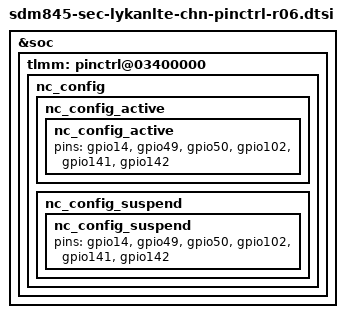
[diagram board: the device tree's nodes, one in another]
/* Copyright (c) 2016-2017, The Linux Foundation. All rights reserved.
 *
 * This program is free software; you can redistribute it and/or modify
 * it under the terms of the GNU General Public License version 2 and
 * only version 2 as published by the Free Software Foundation.
 *
 * This program is distributed in the hope that it will be useful,
 * but WITHOUT ANY WARRANTY; without even the implied warranty of
 * MERCHANTABILITY or FITNESS FOR A PARTICULAR PURPOSE.  See the
 * GNU General Public License for more details.
 */

#include "sdm845-sec-lykanlte-chn-pinctrl-r05.dtsi"


&soc {
	tlmm: pinctrl@03400000 {
		nc_config{
			nc_config_active: nc_config_active {
				nc_config_active {
					pins = "gpio14", "gpio49", "gpio50", "gpio102", "gpio141", "gpio142";
				};
			};

			nc_config_suspend: nc_config_suspend {
				nc_config_suspend {
					pins = "gpio14", "gpio49", "gpio50", "gpio102", "gpio141", "gpio142";
				};
			};
		};
	};
};
